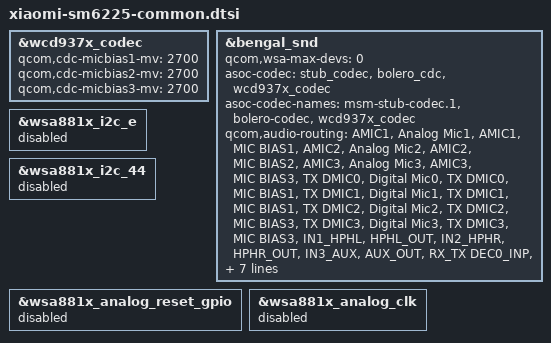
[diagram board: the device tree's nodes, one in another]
&wcd937x_codec {
    qcom,cdc-micbias1-mv = <2700>;
    qcom,cdc-micbias2-mv = <2700>;
    qcom,cdc-micbias3-mv = <2700>;
};

&bengal_snd {
    qcom,wsa-max-devs = <0>;

	asoc-codec  = <&stub_codec>, <&bolero_cdc>,
			<&wcd937x_codec>;
	asoc-codec-names = "msm-stub-codec.1", "bolero-codec",
			"wcd937x_codec";

    qcom,audio-routing =
    	"AMIC1", "Analog Mic1",
    	"AMIC1", "MIC BIAS1",
    	"AMIC2", "Analog Mic2",
    	"AMIC2", "MIC BIAS2",
    	"AMIC3", "Analog Mic3",
    	"AMIC3", "MIC BIAS3",
    	"TX DMIC0", "Digital Mic0",
    	"TX DMIC0", "MIC BIAS1",
    	"TX DMIC1", "Digital Mic1",
    	"TX DMIC1", "MIC BIAS1",
    	"TX DMIC2", "Digital Mic2",
    	"TX DMIC2", "MIC BIAS3",
    	"TX DMIC3", "Digital Mic3",
    	"TX DMIC3", "MIC BIAS3",
    	"IN1_HPHL", "HPHL_OUT",
    	"IN2_HPHR", "HPHR_OUT",
    	"IN3_AUX", "AUX_OUT",
    	"RX_TX DEC0_INP", "TX DEC0 MUX",
    	"RX_TX DEC1_INP", "TX DEC1 MUX",
    	"RX_TX DEC2_INP", "TX DEC2 MUX",
    	"RX_TX DEC3_INP", "TX DEC3 MUX",
    	"TX SWR_INPUT", "WCD_TX_OUTPUT",
    	"VA SWR_INPUT", "VA_SWR_CLK",
    	"VA SWR_INPUT", "WCD_TX_OUTPUT",
    	"TX_AIF1 CAP", "VA_SWR_CLK",
    	"TX_AIF2 CAP", "VA_SWR_CLK",
    	"TX_AIF3 CAP", "VA_SWR_CLK";
};

&wsa881x_i2c_e {
    status = "disable";
};

&wsa881x_i2c_44 {
    status = "disable";
};

&wsa881x_analog_reset_gpio {
    status = "disable";
};

&wsa881x_analog_clk {
    status = "disable";
};
